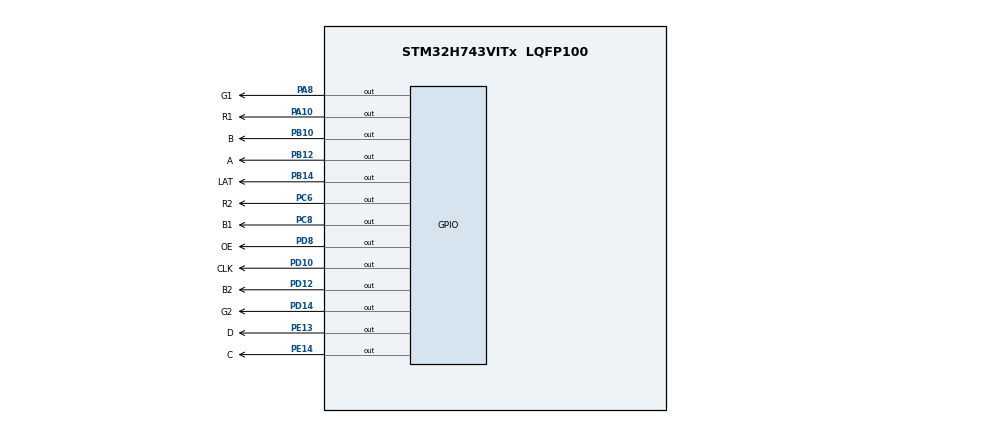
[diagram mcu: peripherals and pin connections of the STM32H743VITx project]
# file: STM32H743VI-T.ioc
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Mcu.Family=STM32H7
Mcu.Name=STM32H743VITx
Mcu.Package=LQFP100
NVIC.PriorityGroup=NVIC_PRIORITYGROUP_4
PA10.GPIO_Label=R1
PA10.Signal=GPIO_Output
PA8.GPIO_Label=G1
PA8.Signal=GPIO_Output
PB10.GPIO_Label=B
PB10.Signal=GPIO_Output
PB12.GPIO_Label=A
PB12.Signal=GPIO_Output
PB14.GPIO_Label=LAT
PB14.Signal=GPIO_Output
PC6.GPIO_Label=R2
PC6.Signal=GPIO_Output
PC8.GPIO_Label=B1
PC8.Signal=GPIO_Output
PD10.GPIO_Label=CLK
PD10.Signal=GPIO_Output
PD12.GPIO_Label=B2
PD12.Signal=GPIO_Output
PD14.GPIO_Label=G2
PD14.Signal=GPIO_Output
PD8.GPIO_Label=OE
PD8.Signal=GPIO_Output
PE13.GPIO_Label=D
PE13.Signal=GPIO_Output
PE14.GPIO_Label=C
PE14.Signal=GPIO_Output
ProjectManager.HeapSize=0x200
ProjectManager.StackSize=0x400
ProjectManager.TargetToolchain=STM32CubeIDE
RCC.ADCFreq_Value=129000000
RCC.APB1Freq_Value=64000000
RCC.APB2Freq_Value=64000000
RCC.APB3Freq_Value=64000000
RCC.APB4Freq_Value=64000000
RCC.CortexFreq_Value=256000000
RCC.DIVM1=8
RCC.DIVN1=64
RCC.HCLKFreq_Value=64000000
RCC.HPRE=RCC_HCLK_DIV4
RCC.SYSCLKFreq_VALUE=256000000
RCC.SYSCLKSource=RCC_SYSCLKSOURCE_PLLCLK
RCC.USBFreq_Value=256000000
board=custom

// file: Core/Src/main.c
/* USER CODE BEGIN Header */
/**
  ******************************************************************************
  * @file           : main.c
  * @brief          : Main program body
  ******************************************************************************
  * @attention
  *
  * <h2><center>&copy; Copyright (c) 2021 STMicroelectronics.
  * All rights reserved.</center></h2>
  *
  * This software component is licensed by ST under BSD 3-Clause license,
  * the "License"; You may not use this file except in compliance with the
  * License. You may obtain a copy of the License at:
  *                        opensource.org/licenses/BSD-3-Clause
  *
  ******************************************************************************
  */
/* USER CODE END Header */
#include "main.h"

/* USER CODE BEGIN Includes */
#include "ledmatrix.h"
/* USER CODE END Includes */

void SystemClock_Config(void);

int main(void)
{

  /* MCU Configuration--------------------------------------------------------*/

  /* Reset of all peripherals, Initializes the Flash interface and the Systick. */
  HAL_Init();

  /* Configure the system clock */
  SystemClock_Config();

  /* Initialize all configured peripherals */

  /* Infinite loop */
  /* USER CODE BEGIN WHILE */
  led_matrix_init();
  uint16_t int_c=0;
  while (1)
  {
	  if (int_c<50) {
		  int_c++;
	  }
	  else{
		  int_c=0;
		  led_matrix_setPixel(0,0,0b111000111);
		  led_matrix_setPixel(1,1,0b000111111);
		  led_matrix_setPixel(2,2,0b111111000);
		  led_matrix_setPixel(3,3,0b000111000);
		  led_matrix_setPixel(4,4,0b111111111);
		  led_matrix_switchBuff();
	  }
	  led_matrix_loop();

    /* USER CODE END WHILE */

  }
}

void SystemClock_Config(void)
{
  RCC_OscInitTypeDef RCC_OscInitStruct = {0};
  RCC_ClkInitTypeDef RCC_ClkInitStruct = {0};

  /** Supply configuration update enable
  */
  HAL_PWREx_ConfigSupply(PWR_LDO_SUPPLY);
  /** Configure the main internal regulator output voltage
  */
  __HAL_PWR_VOLTAGESCALING_CONFIG(PWR_REGULATOR_VOLTAGE_SCALE2);

  while(!__HAL_PWR_GET_FLAG(PWR_FLAG_VOSRDY)) {}
  /** Initializes the RCC Oscillators according to the specified parameters
  * in the RCC_OscInitTypeDef structure.
  */
  RCC_OscInitStruct.OscillatorType = RCC_OSCILLATORTYPE_HSI;
  RCC_OscInitStruct.HSIState = RCC_HSI_DIV1;
  RCC_OscInitStruct.HSICalibrationValue = RCC_HSICALIBRATION_DEFAULT;
  RCC_OscInitStruct.PLL.PLLState = RCC_PLL_ON;
  RCC_OscInitStruct.PLL.PLLSource = RCC_PLLSOURCE_HSI;
  RCC_OscInitStruct.PLL.PLLM = 8;
  RCC_OscInitStruct.PLL.PLLN = 64;
  RCC_OscInitStruct.PLL.PLLP = 2;
  RCC_OscInitStruct.PLL.PLLQ = 2;
  RCC_OscInitStruct.PLL.PLLR = 2;
  RCC_OscInitStruct.PLL.PLLRGE = RCC_PLL1VCIRANGE_3;
  RCC_OscInitStruct.PLL.PLLVCOSEL = RCC_PLL1VCOWIDE;
  RCC_OscInitStruct.PLL.PLLFRACN = 0;
  if (HAL_RCC_OscConfig(&RCC_OscInitStruct) != HAL_OK)
  {
    Error_Handler();
  }
  /** Initializes the CPU, AHB and APB buses clocks
  */
  RCC_ClkInitStruct.ClockType = RCC_CLOCKTYPE_HCLK|RCC_CLOCKTYPE_SYSCLK
                              |RCC_CLOCKTYPE_PCLK1|RCC_CLOCKTYPE_PCLK2
                              |RCC_CLOCKTYPE_D3PCLK1|RCC_CLOCKTYPE_D1PCLK1;
  RCC_ClkInitStruct.SYSCLKSource = RCC_SYSCLKSOURCE_PLLCLK;
  RCC_ClkInitStruct.SYSCLKDivider = RCC_SYSCLK_DIV1;
  RCC_ClkInitStruct.AHBCLKDivider = RCC_HCLK_DIV4;
  RCC_ClkInitStruct.APB3CLKDivider = RCC_APB3_DIV1;
  RCC_ClkInitStruct.APB1CLKDivider = RCC_APB1_DIV1;
  RCC_ClkInitStruct.APB2CLKDivider = RCC_APB2_DIV1;
  RCC_ClkInitStruct.APB4CLKDivider = RCC_APB4_DIV1;

  if (HAL_RCC_ClockConfig(&RCC_ClkInitStruct, FLASH_LATENCY_1) != HAL_OK)
  {
    Error_Handler();
  }
}

void Error_Handler(void)
{
  __disable_irq();
  while (1)
  {
  }
}

/************************ (C) COPYRIGHT STMicroelectronics *****END OF FILE****/
